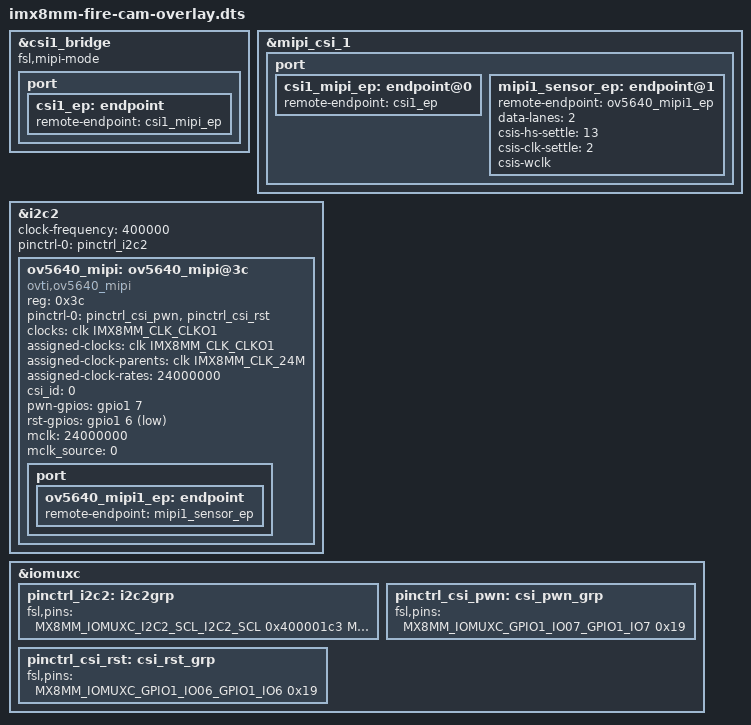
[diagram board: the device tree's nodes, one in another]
/*
 * Copyright (C) 2021 - All Rights Reserved by 
 * filename : imx8mm-fire-cam-overlay.dts
 * brief : Device Tree overlay for ebf imx8mm ov5640 device
 * author : embedfire
 * date : 2021-12-04 
 * version : A001
 */

/dts-v1/;
/plugin/;

#include "../imx8mm-pinfunc.h"
#include "dt-bindings/gpio/gpio.h"
#include "dt-bindings/clock/imx8mm-clock.h"

/ {
	fragment@0 {
		target = <&csi1_bridge>;
		__overlay__ {
			fsl,mipi-mode;
			status = "okay";
			port {
				csi1_ep: endpoint {
					remote-endpoint = <&csi1_mipi_ep>;
				};
			};
		};
	};
	
	fragment@1 {
		target = <&mipi_csi_1>;
		__overlay__{
			#address-cells = <1>;
			#size-cells = <0>;
			status = "okay";
			port {
				/* must before mipi1_sensor_ep  */
				csi1_mipi_ep: endpoint@0 {
					remote-endpoint = <&csi1_ep>;
				};

				mipi1_sensor_ep: endpoint@1 {
					remote-endpoint = <&ov5640_mipi1_ep>;
					data-lanes = <2>;
					csis-hs-settle = <13>;
					csis-clk-settle = <2>;
					csis-wclk;
				};
			};
		};
	};

        fragment@2 {
                target = <&i2c2>;
                __overlay__{
			clock-frequency = <400000>;
			pinctrl-names = "default";
			pinctrl-0 = <&pinctrl_i2c2>;
			status = "okay";
			
			#address-cells = <1>;
                        #size-cells = <0>;

			ov5640_mipi: ov5640_mipi@3c {
				compatible = "ovti,ov5640_mipi";
				reg = <0x3c>;
				status = "okay";
				pinctrl-names = "default";
				pinctrl-0 = <&pinctrl_csi_pwn>, <&pinctrl_csi_rst>;
				clocks = <&clk IMX8MM_CLK_CLKO1>;
				clock-names = "csi_mclk";
				assigned-clocks = <&clk IMX8MM_CLK_CLKO1>;
				assigned-clock-parents = <&clk IMX8MM_CLK_24M>;
				assigned-clock-rates = <24000000>;
				csi_id = <0>;
				pwn-gpios = <&gpio1 7 GPIO_ACTIVE_HIGH>;
				rst-gpios = <&gpio1 6 GPIO_ACTIVE_LOW>;
				mclk = <24000000>;
				mclk_source = <0>;
				port {
					ov5640_mipi1_ep: endpoint {
						remote-endpoint = <&mipi1_sensor_ep>;
					};
				};
			};
		};
	};	

        fragment@3 {
                target= <&iomuxc>;
                __overlay__{
			pinctrl_i2c2: i2c2grp {
				fsl,pins = <
					MX8MM_IOMUXC_I2C2_SCL_I2C2_SCL                  0x400001c3
					MX8MM_IOMUXC_I2C2_SDA_I2C2_SDA                  0x400001c3
				>;
			};

			pinctrl_csi_pwn: csi_pwn_grp {
				fsl,pins = <
					MX8MM_IOMUXC_GPIO1_IO07_GPIO1_IO7               0x19
				>;
			};

			pinctrl_csi_rst: csi_rst_grp {
				fsl,pins = <
					MX8MM_IOMUXC_GPIO1_IO06_GPIO1_IO6               0x19
				>;
			};
                };
        };
};
